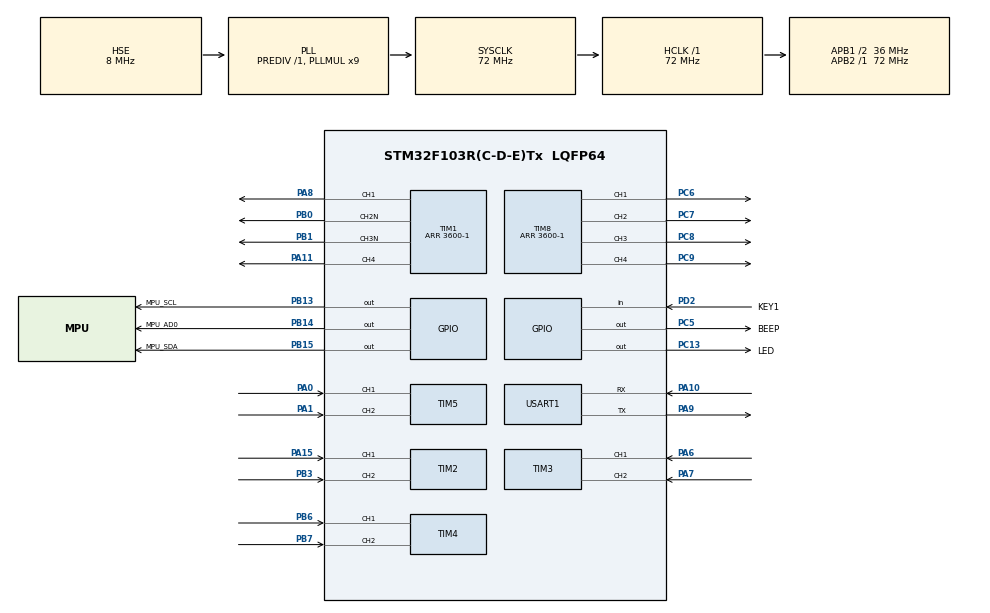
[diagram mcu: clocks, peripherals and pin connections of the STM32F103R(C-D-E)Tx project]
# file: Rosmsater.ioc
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Dma.Request0=USART1_TX
Dma.Request1=USART1_RX
Dma.USART1_RX.1.Direction=DMA_PERIPH_TO_MEMORY
Dma.USART1_RX.1.Instance=DMA1_Channel5
Dma.USART1_RX.1.MemDataAlignment=DMA_MDATAALIGN_BYTE
Dma.USART1_RX.1.MemInc=DMA_MINC_ENABLE
Dma.USART1_RX.1.Mode=DMA_NORMAL
Dma.USART1_RX.1.PeriphDataAlignment=DMA_PDATAALIGN_BYTE
Dma.USART1_RX.1.PeriphInc=DMA_PINC_DISABLE
Dma.USART1_RX.1.Priority=DMA_PRIORITY_LOW
Dma.USART1_TX.0.Direction=DMA_MEMORY_TO_PERIPH
Dma.USART1_TX.0.Instance=DMA1_Channel4
Dma.USART1_TX.0.MemDataAlignment=DMA_MDATAALIGN_BYTE
Dma.USART1_TX.0.MemInc=DMA_MINC_ENABLE
Dma.USART1_TX.0.Mode=DMA_NORMAL
Dma.USART1_TX.0.PeriphDataAlignment=DMA_PDATAALIGN_BYTE
Dma.USART1_TX.0.PeriphInc=DMA_PINC_DISABLE
Dma.USART1_TX.0.Priority=DMA_PRIORITY_LOW
FREERTOS.Tasks01=defaultTask,0,128,StartDefaultTask,Default,NULL,Dynamic,NULL,NULL;myTask_KEY,-3,128,StartTask_KEY,Default,NULL,Dynamic,NULL,NULL;myTask_SERIAL,0,128,StartTask_SERIAL,Default,NULL,Dynamic,NULL,NULL
FREERTOS.configUSE_NEWLIB_REENTRANT=1
Mcu.Family=STM32F1
Mcu.Name=STM32F103R(C-D-E)Tx
Mcu.Package=LQFP64
NVIC.DMA1_Channel4_IRQn=true\:5\:0\:false\:false\:true\:true\:false\:true\:true
NVIC.DMA1_Channel5_IRQn=true\:5\:0\:false\:false\:true\:true\:false\:true\:true
NVIC.PriorityGroup=NVIC_PRIORITYGROUP_4
NVIC.TIM7_IRQn=true\:15\:0\:false\:false\:true\:false\:false\:true\:true
NVIC.TimeBase=TIM7_IRQn
NVIC.TimeBaseIP=TIM7
NVIC.USART1_IRQn=true\:5\:0\:false\:false\:true\:true\:true\:true\:true
PA0-WKUP.Signal=S_TIM5_CH1
PA1.Signal=S_TIM5_CH2
PA10.Mode=Asynchronous
PA10.Signal=USART1_RX
PA11.Signal=S_TIM1_CH4
PA13.Mode=Serial_Wire
PA13.Signal=SYS_JTMS-SWDIO
PA14.Mode=Serial_Wire
PA14.Signal=SYS_JTCK-SWCLK
PA15.Signal=S_TIM2_CH1_ETR
PA6.Signal=S_TIM3_CH1
PA7.Signal=S_TIM3_CH2
PA8.Signal=S_TIM1_CH1
PA9.Mode=Asynchronous
PA9.Signal=USART1_TX
PB0.Mode=PWM Generation2 CH2N
PB0.Signal=TIM1_CH2N
PB1.Mode=PWM Generation3 CH3N
PB1.Signal=TIM1_CH3N
PB13.GPIO_Label=MPU_SCL
PB13.GPIO_PuPd=GPIO_PULLUP
PB13.GPIO_Speed=GPIO_SPEED_FREQ_HIGH
PB13.PinState=GPIO_PIN_SET
PB13.Signal=GPIO_Output
PB14.GPIO_Label=MPU_AD0
PB14.Signal=GPIO_Output
PB15.GPIO_Label=MPU_SDA
PB15.GPIO_PuPd=GPIO_PULLUP
PB15.GPIO_Speed=GPIO_SPEED_FREQ_HIGH
PB15.PinState=GPIO_PIN_SET
PB15.Signal=GPIO_Output
PB3.Signal=S_TIM2_CH2
PB6.Signal=S_TIM4_CH1
PB7.Signal=S_TIM4_CH2
PC13-TAMPER-RTC.GPIO_Label=LED
PC13-TAMPER-RTC.Signal=GPIO_Output
PC5.GPIO_Label=BEEP
PC5.Signal=GPIO_Output
PC6.Signal=S_TIM8_CH1
PC7.Signal=S_TIM8_CH2
PC8.Signal=S_TIM8_CH3
PC9.Signal=S_TIM8_CH4
PD0-OSC_IN.Mode=HSE-External-Oscillator
PD0-OSC_IN.Signal=RCC_OSC_IN
PD1-OSC_OUT.Mode=HSE-External-Oscillator
PD1-OSC_OUT.Signal=RCC_OSC_OUT
PD2.GPIO_Label=KEY1
PD2.Signal=GPIO_Input
ProjectManager.HeapSize=0x200
ProjectManager.StackSize=0x400
ProjectManager.TargetToolchain=STM32CubeIDE
RCC.AHBFreq_Value=72000000
RCC.APB1CLKDivider=RCC_HCLK_DIV2
RCC.APB1Freq_Value=36000000
RCC.APB1TimFreq_Value=72000000
RCC.APB2Freq_Value=72000000
RCC.APB2TimFreq_Value=72000000
RCC.HCLKFreq_Value=72000000
RCC.PLLMUL=RCC_PLL_MUL9
RCC.PLLSourceVirtual=RCC_PLLSOURCE_HSE
RCC.SYSCLKFreq_VALUE=72000000
RCC.SYSCLKSource=RCC_SYSCLKSOURCE_PLLCLK
RCC.USBFreq_Value=72000000
SH.S_TIM1_CH1.0=TIM1_CH1,PWM Generation1 CH1
SH.S_TIM1_CH4.0=TIM1_CH4,PWM Generation4 CH4
SH.S_TIM2_CH1_ETR.0=TIM2_CH1,Encoder_Interface
SH.S_TIM2_CH2.0=TIM2_CH2,Encoder_Interface
SH.S_TIM3_CH1.0=TIM3_CH1,Encoder_Interface
SH.S_TIM3_CH2.0=TIM3_CH2,Encoder_Interface
SH.S_TIM4_CH1.0=TIM4_CH1,Encoder_Interface
SH.S_TIM4_CH2.0=TIM4_CH2,Encoder_Interface
SH.S_TIM5_CH1.0=TIM5_CH1,Encoder_Interface
SH.S_TIM5_CH2.0=TIM5_CH2,Encoder_Interface
SH.S_TIM8_CH1.0=TIM8_CH1,PWM Generation1 CH1
SH.S_TIM8_CH2.0=TIM8_CH2,PWM Generation2 CH2
SH.S_TIM8_CH3.0=TIM8_CH3,PWM Generation3 CH3
SH.S_TIM8_CH4.0=TIM8_CH4,PWM Generation4 CH4
TIM1.AutoReloadPreload=TIM_AUTORELOAD_PRELOAD_ENABLE
TIM1.Channel-PWM\ Generation1\ CH1=TIM_CHANNEL_1
TIM1.Channel-PWM\ Generation2\ CH2N=TIM_CHANNEL_2
TIM1.Channel-PWM\ Generation3\ CH3N=TIM_CHANNEL_3
TIM1.Channel-PWM\ Generation4\ CH4=TIM_CHANNEL_4
TIM1.Period=3600-1
TIM2.EncoderMode=TIM_ENCODERMODE_TI12
TIM3.EncoderMode=TIM_ENCODERMODE_TI12
TIM4.EncoderMode=TIM_ENCODERMODE_TI12
TIM5.EncoderMode=TIM_ENCODERMODE_TI12
TIM8.AutoReloadPreload=TIM_AUTORELOAD_PRELOAD_ENABLE
TIM8.Channel-PWM\ Generation1\ CH1=TIM_CHANNEL_1
TIM8.Channel-PWM\ Generation2\ CH2=TIM_CHANNEL_2
TIM8.Channel-PWM\ Generation3\ CH3=TIM_CHANNEL_3
TIM8.Channel-PWM\ Generation4\ CH4=TIM_CHANNEL_4
TIM8.Period=3600-1
USART1.VirtualMode=VM_ASYNC
VP_FREERTOS_VS_CMSIS_V1.Mode=CMSIS_V1
VP_SYS_VS_tim7.Mode=TIM7
board=custom

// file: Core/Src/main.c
/* USER CODE BEGIN Header */
/**
  ******************************************************************************
  * @file           : main.c
  * @brief          : Main program body
  ******************************************************************************
  * @attention
  *
  * Copyright (c) 2023 STMicroelectronics.
  * All rights reserved.
  *
  * This software is licensed under terms that can be found in the LICENSE file
  * in the root directory of this software component.
  * If no LICENSE file comes with this software, it is provided AS-IS.
  *
  ******************************************************************************
  */
/* USER CODE END Header */
#include "main.h"
#include "cmsis_os.h"
#include "dma.h"
#include "tim.h"
#include "usart.h"
#include "gpio.h"

/* USER CODE BEGIN Includes */
#include "bsp.h"
/* USER CODE END Includes */

void SystemClock_Config(void);
void MX_FREERTOS_Init(void);

int main(void)
{

  /* MCU Configuration--------------------------------------------------------*/

  /* Reset of all peripherals, Initializes the Flash interface and the Systick. */
  HAL_Init();

  /* Configure the system clock */
  SystemClock_Config();

  /* Initialize all configured peripherals */
  MX_GPIO_Init();
  MX_DMA_Init();
  MX_USART1_UART_Init();
  MX_TIM1_Init();
  MX_TIM8_Init();
  MX_TIM2_Init();
  MX_TIM3_Init();
  MX_TIM4_Init();
  MX_TIM5_Init();
  /* USER CODE BEGIN 2 */
  bsp_init();
  /* USER CODE END 2 */

  /* Call init function for freertos objects (in freertos.c) */
  MX_FREERTOS_Init();

  /* Start scheduler */
  osKernelStart();
  /* We should never get here as control is now taken by the scheduler */
  /* Infinite loop */
  while (1)
  {

    /* USER CODE BEGIN 3 */
	  //bsp_loop();
  }
  /* USER CODE END 3 */
}

void SystemClock_Config(void)
{
  RCC_OscInitTypeDef RCC_OscInitStruct = {0};
  RCC_ClkInitTypeDef RCC_ClkInitStruct = {0};

  /** Initializes the RCC Oscillators according to the specified parameters
  * in the RCC_OscInitTypeDef structure.
  */
  RCC_OscInitStruct.OscillatorType = RCC_OSCILLATORTYPE_HSE;
  RCC_OscInitStruct.HSEState = RCC_HSE_ON;
  RCC_OscInitStruct.HSEPredivValue = RCC_HSE_PREDIV_DIV1;
  RCC_OscInitStruct.HSIState = RCC_HSI_ON;
  RCC_OscInitStruct.PLL.PLLState = RCC_PLL_ON;
  RCC_OscInitStruct.PLL.PLLSource = RCC_PLLSOURCE_HSE;
  RCC_OscInitStruct.PLL.PLLMUL = RCC_PLL_MUL9;
  if (HAL_RCC_OscConfig(&RCC_OscInitStruct) != HAL_OK)
  {
    Error_Handler();
  }

  /** Initializes the CPU, AHB and APB buses clocks
  */
  RCC_ClkInitStruct.ClockType = RCC_CLOCKTYPE_HCLK|RCC_CLOCKTYPE_SYSCLK
                              |RCC_CLOCKTYPE_PCLK1|RCC_CLOCKTYPE_PCLK2;
  RCC_ClkInitStruct.SYSCLKSource = RCC_SYSCLKSOURCE_PLLCLK;
  RCC_ClkInitStruct.AHBCLKDivider = RCC_SYSCLK_DIV1;
  RCC_ClkInitStruct.APB1CLKDivider = RCC_HCLK_DIV2;
  RCC_ClkInitStruct.APB2CLKDivider = RCC_HCLK_DIV1;

  if (HAL_RCC_ClockConfig(&RCC_ClkInitStruct, FLASH_LATENCY_2) != HAL_OK)
  {
    Error_Handler();
  }
}

void HAL_TIM_PeriodElapsedCallback(TIM_HandleTypeDef *htim)
{
  if (htim->Instance == TIM7) {
    HAL_IncTick();
  }
}

void Error_Handler(void)
{
  __disable_irq();
  while (1)
  {
  }
}

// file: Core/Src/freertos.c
/* USER CODE BEGIN Header */
/**
  ******************************************************************************
  * File Name          : freertos.c
  * Description        : Code for freertos applications
  ******************************************************************************
  * @attention
  *
  * Copyright (c) 2023 STMicroelectronics.
  * All rights reserved.
  *
  * This software is licensed under terms that can be found in the LICENSE file
  * in the root directory of this software component.
  * If no LICENSE file comes with this software, it is provided AS-IS.
  *
  ******************************************************************************
  */
/* USER CODE END Header */

#include "FreeRTOS.h"
#include "task.h"
#include "main.h"
#include "cmsis_os.h"

osThreadId defaultTaskHandle;
osThreadId myTask_KEYHandle;
osThreadId myTask_SERIALHandle;

void StartDefaultTask(void const * argument);
void StartTask_KEY(void const * argument);
void StartTask_SERIAL(void const * argument);

void MX_FREERTOS_Init(void); /* (MISRA C 2004 rule 8.1) */

/* GetIdleTaskMemory prototype (linked to static allocation support) */
void vApplicationGetIdleTaskMemory( StaticTask_t **ppxIdleTaskTCBBuffer, StackType_t **ppxIdleTaskStackBuffer, uint32_t *pulIdleTaskStackSize );

/* USER CODE BEGIN GET_IDLE_TASK_MEMORY */
static StaticTask_t xIdleTaskTCBBuffer;
static StackType_t xIdleStack[configMINIMAL_STACK_SIZE];

void vApplicationGetIdleTaskMemory( StaticTask_t **ppxIdleTaskTCBBuffer, StackType_t **ppxIdleTaskStackBuffer, uint32_t *pulIdleTaskStackSize )
{
  *ppxIdleTaskTCBBuffer = &xIdleTaskTCBBuffer;
  *ppxIdleTaskStackBuffer = &xIdleStack[0];
  *pulIdleTaskStackSize = configMINIMAL_STACK_SIZE;
  /* place for user code */
}
/* USER CODE END GET_IDLE_TASK_MEMORY */

void MX_FREERTOS_Init(void) {

  /* Create the thread(s) */
  /* definition and creation of defaultTask */
  osThreadDef(defaultTask, StartDefaultTask, osPriorityNormal, 0, 128);
  defaultTaskHandle = osThreadCreate(osThread(defaultTask), NULL);

  /* definition and creation of myTask_KEY */
  osThreadDef(myTask_KEY, StartTask_KEY, osPriorityIdle, 0, 128);
  myTask_KEYHandle = osThreadCreate(osThread(myTask_KEY), NULL);

  /* definition and creation of myTask_SERIAL */
  osThreadDef(myTask_SERIAL, StartTask_SERIAL, osPriorityNormal, 0, 128);
  myTask_SERIALHandle = osThreadCreate(osThread(myTask_SERIAL), NULL);

}

void StartDefaultTask(void const * argument)
{
  /* USER CODE BEGIN StartDefaultTask */

  /* Infinite loop */
  for(;;)
  {
	  //Task_Entity_MPU();
	  bsp_loop();

    osDelay(1);
  }
  /* USER CODE END StartDefaultTask */
}

void StartTask_KEY(void const * argument)
{
  /* USER CODE BEGIN StartTask_KEY */

  /* Infinite loop */
  for(;;)
  {
	  //Task_Entity_KEY();
	  Motor_Test();
	  osDelay(1);
  }
  /* USER CODE END StartTask_KEY */
}

void StartTask_SERIAL(void const * argument)
{
  /* USER CODE BEGIN StartTask_SERIAL */
	//Task_Entity_Usart_RX();
  /* Infinite loop */
  for(;;)
  {
	 Task_Entity_Usart_RX();

    osDelay(1);
  }
  /* USER CODE END StartTask_SERIAL */
}
